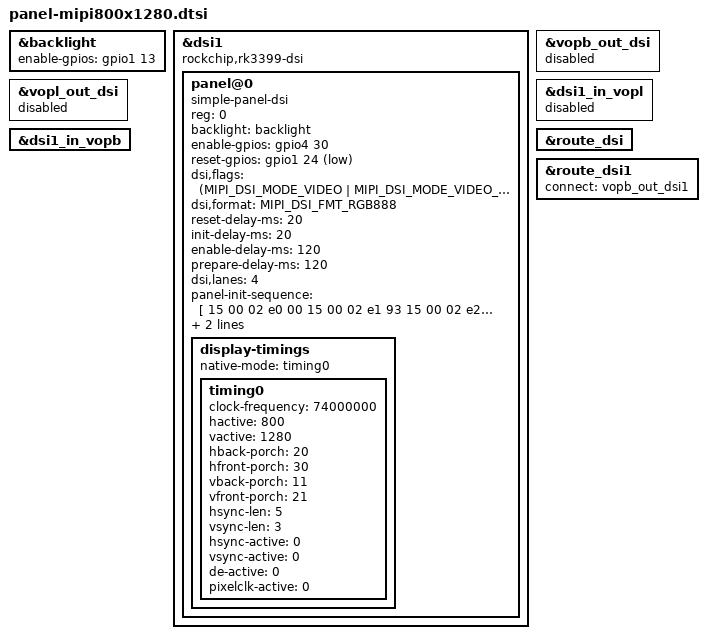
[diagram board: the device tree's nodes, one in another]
/*
 * Copyright (c) 2017 Fuzhou Rockchip Electronics Co., Ltd
 *
 * This file is dual-licensed: you can use it either under the terms
 * of the GPL or the X11 license, at your option. Note that this dual
 * licensing only applies to this file, and not this project as a
 * whole.
 *
 *  a) This file is free software; you can redistribute it and/or
 *     modify it under the terms of the GNU General Public License as
 *     published by the Free Software Foundation; either version 2 of the
 *     License, or (at your option) any later version.
 *
 *     This file is distributed in the hope that it will be useful,
 *     but WITHOUT ANY WARRANTY; without even the implied warranty of
 *     MERCHANTABILITY or FITNESS FOR A PARTICULAR PURPOSE.  See the
 *     GNU General Public License for more details.
 *
 * Or, alternatively,
 *
 *  b) Permission is hereby granted, free of charge, to any person
 *     obtaining a copy of this software and associated documentation
 *     files (the "Software"), to deal in the Software without
 *     restriction, including without limitation the rights to use,
 *     copy, modify, merge, publish, distribute, sublicense, and/or
 *     sell copies of the Software, and to permit persons to whom the
 *     Software is furnished to do so, subject to the following
 *     conditions:
 *
 *     The above copyright notice and this permission notice shall be
 *     included in all copies or substantial portions of the Software.
 *
 *     THE SOFTWARE IS PROVIDED "AS IS", WITHOUT WARRANTY OF ANY KIND,
 *     EXPRESS OR IMPLIED, INCLUDING BUT NOT LIMITED TO THE WARRANTIES
 *     OF MERCHANTABILITY, FITNESS FOR A PARTICULAR PURPOSE AND
 *     NONINFRINGEMENT. IN NO EVENT SHALL THE AUTHORS OR COPYRIGHT
 *     HOLDERS BE LIABLE FOR ANY CLAIM, DAMAGES OR OTHER LIABILITY,
 *     WHETHER IN AN ACTION OF CONTRACT, TORT OR OTHERWISE, ARISING
 *     FROM, OUT OF OR IN CONNECTION WITH THE SOFTWARE OR THE USE OR
 *     OTHER DEALINGS IN THE SOFTWARE.
 */

&backlight {
        status = "okay";
        enable-gpios = <&gpio1 13 GPIO_ACTIVE_HIGH>;
};

&dsi1 {

	compatible = "rockchip,rk3399-dsi";
        //enable-gpios = <&gpio4 30 GPIO_ACTIVE_HIGH>;
        //reset-gpios = <&gpio1 24 GPIO_ACTIVE_LOW>;
        status = "okay";

	panel@0 {
		compatible = "simple-panel-dsi";
		reg = <0>;
		backlight = <&backlight>;
		enable-gpios = <&gpio4 30 GPIO_ACTIVE_HIGH>;
		reset-gpios = <&gpio1 24 GPIO_ACTIVE_LOW>;
		dsi,flags = <(MIPI_DSI_MODE_VIDEO | MIPI_DSI_MODE_VIDEO_BURST |
			      MIPI_DSI_MODE_LPM | MIPI_DSI_MODE_EOT_PACKET)>;
		dsi,format = <MIPI_DSI_FMT_RGB888>;
		reset-delay-ms = <20>;                                                           
		init-delay-ms = <20>;                                                            
		enable-delay-ms = <120>;                                                         
		prepare-delay-ms = <120>;   
		dsi,lanes = <4>;

	panel-init-sequence = [   
								15  00  02  e0  00 
							  15  00  02  e1  93 
							  15  00  02  e2  65 
							  15  00  02  e3  f8 
							  15  00  02  80  03 
							  15  00  02  E0  04 
							  15  00  02  2D  03 
							  15  00  02  E0  01 
							  15  00  02  00  00 
							  15  00  02  01  7b 
							  15  00  02  17  00 
							  15  00  02  18  c2 
							  15  00  02  19  01 
							  15  00  02  1a  00 
							  15  00  02  1b  c2 
							  15  00  02  1c  01 
							  15  00  02  1f  3f 
							  15  00  02  20  24 
							  15  00  02  21  24 
							  15  00  02  22  0e 
							  15  00  02  37  09 
							  15  00  02  38  04 
							  15  00  02  39  00 
							  15  00  02  3a  01 
							  15  00  02  3c  78 
							  15  00  02  3d  ff 
							  15  00  02  3e  ff 
							  15  00  02  3f  ff 
							  15  00  02  40  06 
							  15  00  02  41  a0 
							  15  00  02  43  10 
							  15  00  02  44  07 
							  15  00  02  45  28 
							  15  00  02  55  01 
							  15  00  02  56  01 
							  15  00  02  57  68 
							  15  00  02  58  0a 
							  15  00  02  59  2a 
							  15  00  02  5a  28 
							  15  00  02  5b  0f 
							  15  00  02  5d  7c 
							  15  00  02  5e  67 
							  15  00  02  5f  55 
							  15  00  02  60  48 
							  15  00  02  61  3e 
							  15  00  02  62  2d 
							  15  00  02  63  30 
							  15  00  02  64  16 
							  15  00  02  65  2c 
							  15  00  02  66  28 
							  15  00  02  67  26 
							  15  00  02  68  42 
							  15  00  02  69  30 
							  15  00  02  6a  38 
							  15  00  02  6b  29 
							  15  00  02  6c  26 
							  15  00  02  6d  1c 
							  15  00  02  6e  0d 
							  15  00  02  6f  00 
							  15  00  02  70  7c 
							  15  00  02  71  69 
							  15  00  02  72  55 
							  15  00  02  73  48 
							  15  00  02  74  3e 
							  15  00  02  75  2d 
							  15  00  02  76  30 
							  15  00  02  77  16 
							  15  00  02  78  2c 
							  15  00  02  79  28 
							  15  00  02  7a  26 
							  15  00  02  7b  42 
							  15  00  02  7c  30 
							  15  00  02  7d  38 
							  15  00  02  7e  29 
							  15  00  02  7f  26 
							  15  00  02  80  1c 
							  15  00  02  81  0d 
							  15  00  02  82  00 
							  15  00  02  e0  02 
							  15  00  02  00  09 
							  15  00  02  01  05 
							  15  00  02  02  08 
							  15  00  02  03  04 
							  15  00  02  04  06 
							  15  00  02  05  0a 
							  15  00  02  06  07 
							  15  00  02  07  0b 
							  15  00  02  08  00 
							  15  00  02  09  1f 
							  15  00  02  0a  1f 
							  15  00  02  0b  1f 
							  15  00  02  0c  1f 
							  15  00  02  0d  1f 
							  15  00  02  0e  1f 
							  15  00  02  0f  17 
							  15  00  02  10  37 
							  15  00  02  11  1f 
							  15  00  02  12  1f 
							  15  00  02  13  1e 
							  15  00  02  14  10 
							  15  00  02  15  1f 
							  15  00  02  16  09 
							  15  00  02  17  05 
							  15  00  02  18  08 
							  15  00  02  19  04 
							  15  00  02  1a  06 
							  15  00  02  1b  0a 
							  15  00  02  1c  07   
							  15  00  02  1d  0b 
							  15  00  02  1e  00 
							  15  00  02  1f  1f 
							  15  00  02  20  1f 
							  15  00  02  21  1f 
							  15  00  02  22  1f 
							  15  00  02  23  1f 
							  15  00  02  24  1f 
							  15  00  02  25  17 
							  15  00  02  26  37 
							  15  00  02  27  1f 
							  15  00  02  28  1f 
							  15  00  02  29  1e 
							  15  00  02  2a  10 
							  15  00  02  2b  1f       
							  15  00  02  58  01     
							  15  00  02  5b  00 
							  15  00  02  5c  01 
							  15  00  02  5d  70 
							  15  00  02  5e  00   
							  15  00  02  5f  00 
							  15  00  02  60  40 
							  15  00  02  61  00 
							  15  00  02  62  00 
							  15  00  02  63  65 
							  15  00  02  64  65 
							  15  00  02  65  45 
							  15  00  02  66  09 
							  15  00  02  67  73 
							  15  00  02  68  05 
							  15  00  02  69  00 
							  15  00  02  6a  64 
							  15  00  02  6b  00 
							  15  00  02  6c  00 
							  15  00  02  6d  00 
							  15  00  02  6e  00 
							  15  00  02  6f  88 
							  15  00  02  75  80 
							  15  00  02  76  00 
							  15  00  02  77  05 
							  15  00  02  78  18 
							  15  00  02  e0  04 
							  15  00  02  2b  2b 
							  15  00  02  2e  44 
							  15  00  02  e0  00 
							  15  00  02  e6  02 
							  15  00  02  e7  06 
							  05  64  01  11 
							  05  05  01  29 
							  15  00  02  35  00 

		              ];                                                                                             
    panel-exit-sequence = [                                                                                                        
	        05 00 01 28                                                                         
		      05 78 01 10                                                                         
         ];  

		display-timings {
			native-mode = <&timing0>;

			timing0: timing0 {
				clock-frequency = <74000000>;
				hactive = <800>;
				vactive = <1280>;
				hback-porch = <20>;
				hfront-porch = <30>;
				vback-porch = <11>;
				vfront-porch = <21>;
				hsync-len = <5>;
				vsync-len = <3>;
				hsync-active = <0>;
				vsync-active = <0>;
				de-active = <0>;
				pixelclk-active = <0>;
			};
		};
	};
};

&vopb_out_dsi {
	status = "disabled";
};
&vopl_out_dsi {
	status = "disabled";
};

&dsi1_in_vopl {
	status = "disabled";
};

&dsi1_in_vopb {
	status = "okay";
};
&route_dsi {
	status = "okay";
};
&route_dsi1 {
	status = "okay";
	connect = <&vopb_out_dsi1>;
};
